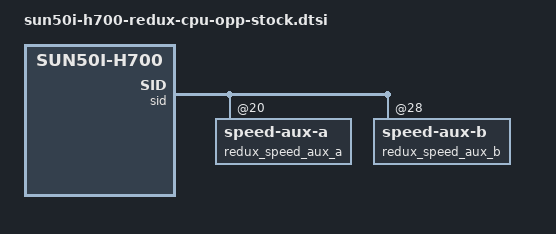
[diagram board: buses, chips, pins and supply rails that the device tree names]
// SPDX-License-Identifier: (GPL-2.0-only OR BSD-2-Clause)
/*
 * Stock-parity CPU OPPs for the RG34XX-SP. DRAFT, NOT BOOTED. GENERATED by
 * phase2-mainline/tools/gen_cpu_opp_stock.py from reference/stock-202505/board.dts; do not edit.
 * Needs the Redux cpufreq xlate (design doc §2a), compatible "anbernic,rg34xx-sp-operating-points".
 * opp-supported-hw bits (Redux numbering): 0 = stock mask 0x1, 1 = mask 0x2, 3 = mask 0x8 (default),
 * 2 = a1, 4 = b0, 5 = b1, 6 = c0, 7 = c1, 8 = c2. Frequencies/voltages are stock's own values.
 */

/ {
	redux_cpu_opp_stock: opp-table-reduxstock {
		compatible = "anbernic,rg34xx-sp-operating-points";
		nvmem-cells = <&cpu_speed_grade>, <&redux_speed_aux_a>, <&redux_speed_aux_b>;
		nvmem-cell-names = "speed", "speed-aux-a", "speed-aux-b";
		opp-shared;

		opp-480000000 {
			opp-hz = /bits/ 64 <480000000>;
			opp-microvolt = <900000>;
			clock-latency-ns = <244144>;
			opp-supported-hw = <0x1ff>;
		};

		opp-600000000 {
			opp-hz = /bits/ 64 <600000000>;
			opp-microvolt = <900000>;
			clock-latency-ns = <244144>;
			opp-supported-hw = <0x15b>;
		};

		opp-720000000 {
			opp-hz = /bits/ 64 <720000000>;
			opp-microvolt-speed2 = <900000>;
			opp-microvolt-speed5 = <900000>;
			opp-microvolt-speed7 = <950000>;
			clock-latency-ns = <244144>;
			opp-supported-hw = <0xa4>;
		};

		opp-792000000 {
			opp-hz = /bits/ 64 <792000000>;
			opp-microvolt-speed0 = <900000>;
			opp-microvolt-speed1 = <900000>;
			opp-microvolt-speed3 = <940000>;
			opp-microvolt-speed4 = <900000>;
			opp-microvolt-speed6 = <940000>;
			opp-microvolt-speed8 = <940000>;
			clock-latency-ns = <244144>;
			opp-supported-hw = <0x15b>;
		};

		opp-936000000 {
			opp-hz = /bits/ 64 <936000000>;
			opp-microvolt-speed5 = <900000>;
			opp-microvolt-speed7 = <950000>;
			clock-latency-ns = <244144>;
			opp-supported-hw = <0xa0>;
		};

		opp-1008000000 {
			opp-hz = /bits/ 64 <1008000000>;
			opp-microvolt-speed0 = <920000>;
			opp-microvolt-speed1 = <900000>;
			opp-microvolt-speed3 = <1020000>;
			opp-microvolt-speed4 = <920000>;
			opp-microvolt-speed5 = <950000>;
			opp-microvolt-speed6 = <1020000>;
			opp-microvolt-speed7 = <1000000>;
			opp-microvolt-speed8 = <1020000>;
			clock-latency-ns = <244144>;
			opp-supported-hw = <0x1fb>;
		};

		opp-1032000000 {
			opp-hz = /bits/ 64 <1032000000>;
			opp-microvolt = <900000>;
			clock-latency-ns = <244144>;
			opp-supported-hw = <0x4>;
		};

		opp-1104000000 {
			opp-hz = /bits/ 64 <1104000000>;
			opp-microvolt-speed2 = <950000>;
			opp-microvolt-speed5 = <1000000>;
			opp-microvolt-speed7 = <1050000>;
			clock-latency-ns = <244144>;
			opp-supported-hw = <0xa4>;
		};

		opp-1200000000 {
			opp-hz = /bits/ 64 <1200000000>;
			opp-microvolt-speed0 = <980000>;
			opp-microvolt-speed1 = <960000>;
			opp-microvolt-speed2 = <1000000>;
			opp-microvolt-speed3 = <1100000>;
			opp-microvolt-speed4 = <980000>;
			opp-microvolt-speed5 = <1050000>;
			opp-microvolt-speed6 = <1100000>;
			opp-microvolt-speed7 = <1100000>;
			opp-microvolt-speed8 = <1100000>;
			clock-latency-ns = <244144>;
			opp-supported-hw = <0x1ff>;
		};

		opp-1296000000 {
			opp-hz = /bits/ 64 <1296000000>;
			opp-microvolt-speed1 = <1100000>;
			opp-microvolt-speed2 = <1050000>;
			opp-microvolt-speed3 = <1120000>;
			clock-latency-ns = <244144>;
			opp-supported-hw = <0xe>;
		};

		opp-1320000000 {
			opp-hz = /bits/ 64 <1320000000>;
			opp-microvolt-speed5 = <1100000>;
			opp-microvolt-speed7 = <1160000>;
			clock-latency-ns = <244144>;
			opp-supported-hw = <0xa0>;
		};

		opp-1344000000 {
			opp-hz = /bits/ 64 <1344000000>;
			opp-microvolt = <1120000>;
			clock-latency-ns = <244144>;
			opp-supported-hw = <0x140>;
		};

		opp-1416000000 {
			opp-hz = /bits/ 64 <1416000000>;
			opp-microvolt-speed2 = <1100000>;
			opp-microvolt-speed5 = <1150000>;
			clock-latency-ns = <244144>;
			opp-supported-hw = <0x24>;
		};

		opp-1512000000 {
			opp-hz = /bits/ 64 <1512000000>;
			opp-microvolt-speed0 = <1120000>;
			opp-microvolt-speed2 = <1160000>;
			opp-microvolt-speed4 = <1120000>;
			opp-microvolt-speed5 = <1160000>;
			clock-latency-ns = <244144>;
			opp-supported-hw = <0x35>;
		};
	};
};

&sid {
	/* SID words +0x220 / +0x228 (value_offset 0x200), read by the stock decoder for fuse 0x5c00. */
	redux_speed_aux_a: speed-aux-a@20 {
		reg = <0x20 0x4>;
	};

	redux_speed_aux_b: speed-aux-b@28 {
		reg = <0x28 0x4>;
	};
};

&cpu0 {
	operating-points-v2 = <&redux_cpu_opp_stock>;
};

&cpu1 {
	operating-points-v2 = <&redux_cpu_opp_stock>;
};

&cpu2 {
	operating-points-v2 = <&redux_cpu_opp_stock>;
};

&cpu3 {
	operating-points-v2 = <&redux_cpu_opp_stock>;
};
